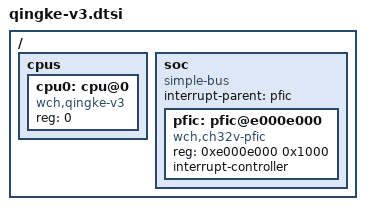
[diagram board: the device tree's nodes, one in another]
/*
 * Copyright (c) 2023-2024 Chen Xingyu <hi@xingrz.me>
 * SPDX-License-Identifier: Apache-2.0
 */

/ {
	cpus {
		#address-cells = <1>;
		#size-cells = <0>;

		cpu0: cpu@0 {
			compatible = "wch,qingke-v3";
			reg = <0>;
		};
	};

	soc {
		compatible = "simple-bus";
		#address-cells = <1>;
		#size-cells = <1>;
		interrupt-parent = <&pfic>;

		pfic: pfic@e000e000 {
			compatible = "wch,ch32v-pfic";
			reg = <0xe000e000 0x1000>;
			interrupt-controller;
			#interrupt-cells = <2>;
		};
	};
};
